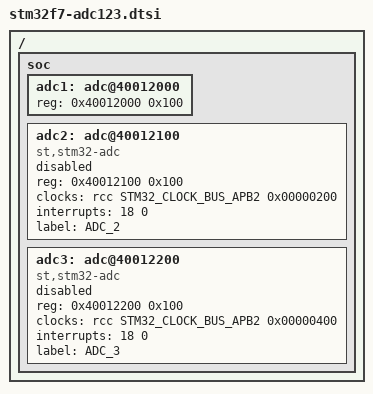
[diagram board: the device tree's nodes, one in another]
/*
 * Copyright (c) 2021 Li-Pro.Net
 * SPDX-License-Identifier: Apache-2.0
 *
 * see "STM32: Multiple ADCs using same interrupt not possible"
 *     https://github.com/zephyrproject-rtos/zephyr/issues/26874
 * and also "stm32f4 error in adc register size in dtsi files"
 *     https://github.com/zephyrproject-rtos/zephyr/issues/30977
 */

/ {
	soc {
		/*
		 * ADCs 1-3 share the same IRQ line on STM32 devices. This
		 * configuration is not currently supported, so at most one
		 * of these may be enabled at a time. Enabling more than one
		 * will result in a build failure, e.g.:
		 *
		 * gen_isr_tables.py: error:
		 *   multiple registrations at table_index 18 for irq 18 (0x12)
		 *   Existing handler 0x801c283, new handler 0x801c283
		 *   Has IRQ_CONNECT or IRQ_DIRECT_CONNECT accidentally been
		 *   invoked on the same irq multiple times?
		 *
		 * Further there is also a common register area afterwards on
		 * reg = <0x40012300 0x100> -- Open issue: How to deal with the
		 * common register settings?
		 */

		// wrong register size in st/f7/stm32f7.dtsi
		adc1: adc@40012000 {
			reg = <0x40012000 0x100>;
		};

		// missed in st/f7/stm32f7.dtsi
		adc2: adc@40012100 {
			compatible = "st,stm32-adc";
			reg = <0x40012100 0x100>;
			clocks = <&rcc STM32_CLOCK_BUS_APB2 0x00000200>;
			interrupts = <18 0>;
			status = "disabled";
			label = "ADC_2";
			#io-channel-cells = <1>;
		};

		// missed in st/f7/stm32f7.dtsi
		adc3: adc@40012200 {
			compatible = "st,stm32-adc";
			reg = <0x40012200 0x100>;
			clocks = <&rcc STM32_CLOCK_BUS_APB2 0x00000400>;
			interrupts = <18 0>;
			status = "disabled";
			label = "ADC_3";
			#io-channel-cells = <1>;
		};
	};
};
